# a34g43x register map
Vendor: ABOV Semiconductor Co., Ltd.; File version: 1.0
CPU: CM4 r0p1, little endian, MPU, FPU, VTOR, 4 interrupt priority bits
Registers are 32-bit, read-write, reset 0x0 unless marked. A register's access mark holds for its fields unless they carry their own. Offsets are from the block's base; [hi:lo] are bit positions; {n}, {i} and the like mark numbered series; 'fields as' and 'values as' point back to an identical list.

## MPWM0 — Motor Pulse Width Modulation
Base 0x41014000
Same registers: MPWM1 0x41014100
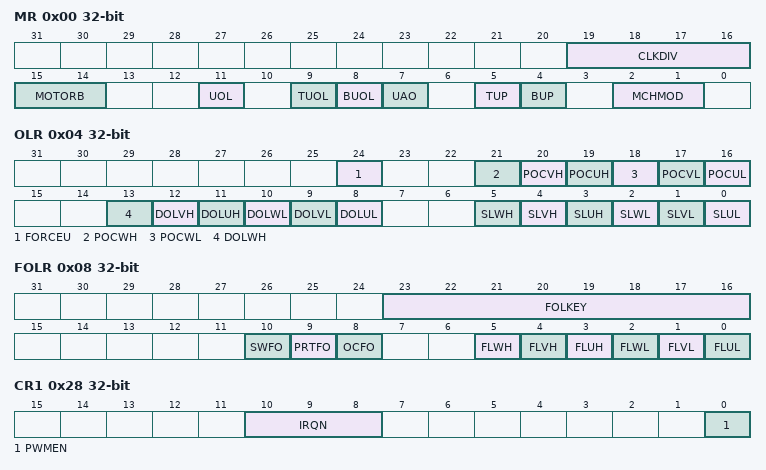
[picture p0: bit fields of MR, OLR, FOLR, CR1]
0x00 MR — MPWM n Mode Register
  [19:16] CLKDIV — MPWM Clock Divider setting bit
  [15:14] MOTORB — MPWM Mode Selection Bit
    0=MOTOR_PWM_MODE_0 (Motor PWM Mode 0(up-down count pwm)); 1=MOTOR_PWM_MODE_1 (Motor PWM Mode 1(up count pwm)); 2=NORMAL_PWM_MODE
  [11] UOL — Output level update timing setting bit
    0=SPECIPIC (Updates at specified timings); 1=ONCE (Updates all output levels at once)
  [9] TUOL — Output level update setting bit(when same period)
    0=NOT_UPDATED (MPWM_OLR register is not updated at every period-match); 1=UPDATED (MPWM_OLR register is updated at every period-match.)
  [8] BUOL — Output level update setting bit(when same bottom)
    0=NOT_UPDATED (MPWM_OLR register is not updated at every bottom-match); 1=UPDATED (MPWM_OLR register is updated at every bottom-match.)
  [7] UAO — Update Timing Selection Bit
    0=DESIGNATE (Designate timing update); 1=ONCE (Once Duty Period Update)
  [5] TUP — DUTY, Period Update Enable bit (When same period)
    0=None Update; 1=Update
  [4] BUP — DUTY, Period Update Enable bit (When same bottom)
    0=None Update; 1=Update
  [2:1] MCHMOD — Channel Symmetry/Asymmetry Mode Selection Bit
    0=2-ch symmetry mode; 1=1-ch asymmetry mode; 2=1-ch symmetry mode
0x04 OLR — MPWM n Output Level Register
  [24] FORCEU — Upper output settings
    0=Separated (6-channel mode); 1=Force_U_channel (All outputs of MPWMxH/ MPWMxL are controlled according to the MPWM_DUH/DUL registers)
  [21] POCWH — WH PWM output control
    0=OFF (Disable); 1=ON (Enable)
  [20] POCVH — VH PWM output control
    0=OFF (Disable); 1=ON (Enable)
  [19] POCUH — UH PWM output control
    0=OFF (Disable); 1=ON (Enable)
  [18] POCWL — WL PWM output control
    0=OFF (Disable); 1=ON (Enable)
  [17] POCVL — VL PWM output control
    0=OFF (Disable); 1=ON (Enable)
  [16] POCUL — UL PWM output control
    0=OFF (Disable); 1=ON (Enable)
  [13] DOLWH — Output level selection bit when PWMxH Disable
    0=LOW (Low Level); 1=HIGH (High Level)
  [12] DOLVH — Output level selection bit when PWMxH Disable
    0=LOW (Low Level); 1=HIGH (High Level)
  [11] DOLUH — Output level selection bit when PWMxH Disable
    0=LOW (Low Level); 1=HIGH (High Level)
  [10] DOLWL — Output level selection bit when PWMxL Disable
    0=LOW (Low Level); 1=HIGH (High Level)
  [9] DOLVL — Output level selection bit when PWMxL Disable
    0=LOW (Low Level); 1=HIGH (High Level)
  [8] DOLUL — Output level selection bit when PWMxL Disable
    0=LOW (Low Level); 1=HIGH (High Level)
  [5] SLWH — Output selection bit when starting WH PWM
    0=LOW (Basic output level (Low Level)); 1=HIGH (Inverted output level (High Level))
  [4] SLVH — Output selection bit when starting VH PWM
    values as SLWH
  [3] SLUH — Output selection bit when starting UH PWM
    values as SLWH
  [2] SLWL — Output selection bit when starting WL PWM
    values as SLWH
  [1] SLVL — Output selection bit when starting VL PWM
    values as SLWH
  [0] SLUL — Output selection bit when starting UL PWM
    values as SLWH
0x08 FOLR — MPWM n compulsion Output Register
  [23:16] FOLKEY wo — Forced output level register access key (FOLR key: 0xCA)
  [10] SWFO — Software forced output settings
    0=PWM (Outputs PWM.); 1=Forced_level (Outputs forced level instead of PWM.)
  [9] PRTFO — Protection forced output settings
    values as SWFO
  [8] OCFO — Over-current forced output settings
    values as SWFO
  [5] FLWH — WH output forced level selection
    0=LOW (Output forced low level); 1=HIGH (Output forced high level)
  [4] FLVH — VH output forced level selection
    values as FLWH
  [3] FLUH — UH output forced level selection
    values as FLWH
  [2] FLWL — WL output forced level selection
    values as FLWH
  [1] FLVL — VL output forced level selection
    values as FLWH
  [0] FLUL — UL output forced level selection
    values as FLWH
0x0C PRD — MPWM n Period Register
  [15:0] PERIOD — 16bit pwm period
0x10 DUH — MPWM n DUTY x Register
  [15:0] DUTY_UH — 16 bit PWM Duty setting bit for X output
0x14 DVH — MPWM n DUTY x Register
  [15:0] DUTY_VH — 16 bit PWM Duty setting bit for X output
0x18 DWH — MPWM n DUTY x Register
  [15:0] DUTY_WH — 16 bit PWM Duty setting bit for X output
0x1C DUL — MPWM n DUTY x Register
  [15:0] DUTY_UL — 16 bit PWM Duty setting bit for X output
0x20 DVL — MPWM n DUTY x Register
  [15:0] DUTY_VL — 16 bit PWM Duty setting bit for X output
0x24 DWL — MPWM n DUTY x Register
  [15:0] DUTY_WL — 16 bit PWM Duty setting bit for X output
0x28 CR1 — MPWM n Control Register 1
  [10:8] IRQN — IRQ number
  [0] PWMEN — PWM Enable Bit
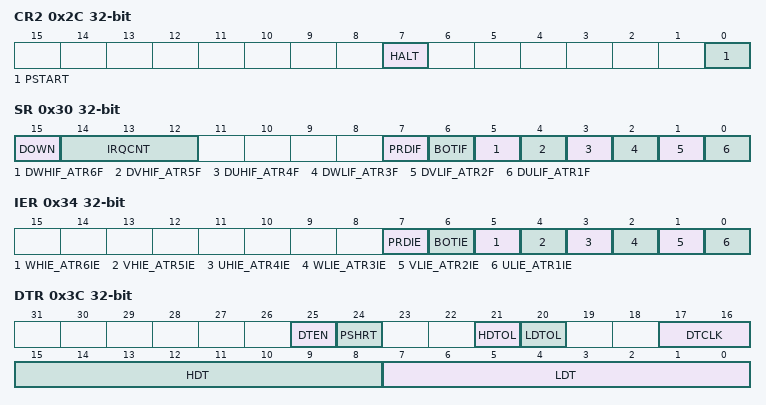
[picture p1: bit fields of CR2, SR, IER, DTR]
0x2C CR2 — MPWM n Control Register 2
  [7] HALT — PWM HALT
  [0] PSTART — PWM Phase x counter start
0x30 SR — MPWM n Status Register
  [15] DOWN ro — Current PWM Counter Mode
  [14:12] IRQCNT ro — Interrupt Counter Number of Period Match
  [7] PRDIF — PWM Period Interrupt Flag
  [6] BOTIF — PWM Bottom Interrupt Flag
  [5] DWHIF_ATR6F — PWM Duty Interrupt Flag (Duty Interrupt Enable when ATR6 disable)
  [4] DVHIF_ATR5F — PWM Duty Interrupt Flag (Duty Interrupt Enable when ATR6 disable)
  [3] DUHIF_ATR4F — PWM Duty Interrupt Flag (Duty Interrupt Enable when ATR6 disable)
  [2] DWLIF_ATR3F — PWM Duty Interrupt Flag (Duty Interrupt Enable when ATR6 disable)
  [1] DVLIF_ATR2F — PWM Duty Interrupt Flag (Duty Interrupt Enable when ATR6 disable)
  [0] DULIF_ATR1F — PWM Duty Interrupt Flag (Duty Interrupt Enable when ATR6 disable)
0x34 IER — MPWM n Interrupt Enable Register
  [7] PRDIE — PWM Counter Period Interrupt Enable bit
  [6] BOTIE — PWM Counter Botom Interrupt Enable bit
  [5] WHIE_ATR6IE — Duty or ATR6 Match Interrupt Enable bit
  [4] VHIE_ATR5IE — Duty or ATR5 Match Interrupt Enable bit
  [3] UHIE_ATR4IE — Duty or ATR4 Match Interrupt Enable bit
  [2] WLIE_ATR3IE — Duty or ATR3 Match Interrupt Enable bit
  [1] VLIE_ATR2IE — Duty or ATR2 Match Interrupt Enable bit
  [0] ULIE_ATR1IE — Duty or ATR1 Match Interrupt Enable bit
0x38 CNT — MPWM n Counter Register
  [15:0] CNT ro — PWM Counter Value
0x3C DTR — MPWM n Dead-Time Register
  [25] DTEN — Dead time function enable
    0=Disables dead time function; 1=Enables dead time function
  [24] PSHRT — Short condition protection
    0=Disables short condition protection; 1=Enables short condition protection
  [21] HDTOL — Output level during dead-time at high side
    0=Low level during dead-time; 1=High level during dead-time
  [20] LDTOL — Output level during dead-time at low side
    0=Low level during dead-time; 1=High level during dead-time
  [17:16] DTCLK — Dead time prescaler
    0=PWM_CLK/2 (Dead time counter uses PWM CLK/2.); 1=PWM_CLK/4 (Dead time counter uses PWM CLK/4.); 2=PWM_CLK/8 (Dead time counter uses PWM CLK/8.); 3=PWM_CLK/16 (Dead time counter uses PWM CLK/16.)
  [15:8] HDT — H side dead time value. 0x01 to 0xFF: dead time
  [7:0] LDT — L side dead time value. 0x01 to 0xFF: dead time
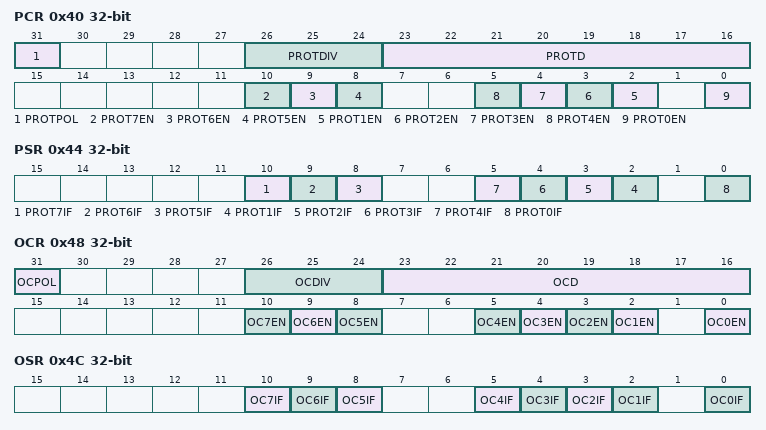
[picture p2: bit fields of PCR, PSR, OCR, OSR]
0x40 PCR — MPWM n Protection Control Register
  [31] PROTPOL — PRTIN Pin Input Polarity settings
  [26:24] PROTDIV — PRTIN Pin debounce divider settings. 2^(PROTDIV[2:0])
  [23:16] PROTD — PRTIN Pin debounce counter settings
  [10] PROT7EN — ADC2_CMPR1 protection operation enable
  [9] PROT6EN — ADC1_CMPR1 protection operation enable
  [8] PROT5EN — ADC0_CMPR1 protection operation enable
  [n+1] PROT{n}EN (n=1..4) — CMP{n-1} protection operation enable
  [0] PROT0EN — PRTIN Pin protection operation enable
0x44 PSR — MPWM n Protection Status Register
  [10] PROT7IF — ADC2_CMPR1 protection interrupt flag
  [9] PROT6IF — ADC1_CMPR1 protection interrupt flag
  [8] PROT5IF — ADC0_CMPR1 protection interrupt flag
  [n+1] PROT{n}IF (n=1..4) — CMP{n-1} protection interrupt flag
  [0] PROT0IF — PRTIN Pin protection interrupt flag
0x48 OCR — MPWM n Overvoltage Control Register
  [31] OCPOL — OCIN Pin Input Polarity settings
  [26:24] OCDIV — OCIN Pin debounce divider settings. 2^(OCINDIV[2:0])
  [23:16] OCD — OCIN Pin debounce counter settings
  [10] OC7EN — ADC2_CMPR1 protection operation enable
  [9] OC6EN — ADC1_CMPR1 protection operation enable
  [8] OC5EN — ADC0_CMPR1 protection operation enable
  [n+1] OC{n}EN (n=1..4) — CMP{n-1} protection operation enable
  [0] OC0EN — PRTIN Pin protection operation enable
0x4C OSR — MPWM n Overvoltage Status Register
  [10] OC7IF — ADC2_CMPR1 protection interrupt flag
  [9] OC6IF — ADC1_CMPR1 protection interrupt flag
  [8] OC5IF — ADC0_CMPR1 protection interrupt flag
  [n+1] OC{n}IF (n=1..4) — CMP{n-1} protection interrupt flag
  [0] OC0IF — PRTIN Pin protection interrupt flag
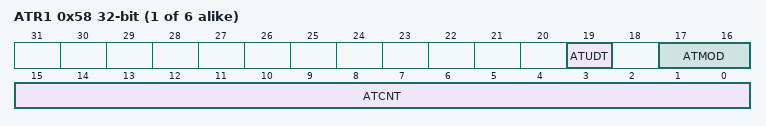
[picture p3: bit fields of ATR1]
{0x54+4i} ATR{i} (i=1..6) — MPWM n ADC Trigger Counter m Register
  [19] ATUDT — ADC Register Update Mode
  [17:16] ATMOD — ADC Trigger Mode Selection Register
    0=Disable (ADC Trigger Disable); 1=UP_Count (Trigger out When up counter match); 2=DOWN_Count (Trigger out When down counter match); 3=UPDOWN_Count (Trigger out When up-down counter match)
  [15:0] ATCNT — ADC Trigger Counter (only less then PWM Period)
